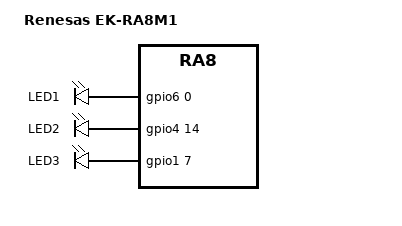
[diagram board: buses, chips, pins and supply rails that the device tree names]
/*
 * Copyright (c) 2024 Renesas Electronics Corporation
 * SPDX-License-Identifier: Apache-2.0
 */

/dts-v1/;

#include <renesas/ra/ra8/r7fa8m1ahecbd.dtsi>
#include <dt-bindings/gpio/gpio.h>

#include "ek_ra8m1-pinctrl.dtsi"

/ {
	model = "Renesas EK-RA8M1";
	compatible = "renesas,ra8m1", "renesas,ra8";

	chosen {
		zephyr,sram = &sram0;
		zephyr,flash = &flash0;
	};

	leds {
		compatible = "gpio-leds";
		led0: led0 {
			gpios = <&gpio6 0 GPIO_ACTIVE_HIGH>;
			label = "LED1";
		};
		led1: led1 {
			gpios = <&gpio4 14 GPIO_ACTIVE_HIGH>;
			label = "LED2";
		};
		led2: led2 {
			gpios = <&gpio1 7 GPIO_ACTIVE_HIGH>;
			label = "LED3";
		};
	};

	aliases {
		led0 = &led0;
	};
};

&clock {
	sciclk-source = <RA_CLOCK_SOURCE_PLL1P>;
	sciclk-div = <RA_SCI_CLOCK_DIV_4>;
};

&gpio1 {
	status = "okay";
};

&gpio4 {
	status = "okay";
};

&gpio6 {
	status = "okay";
};
